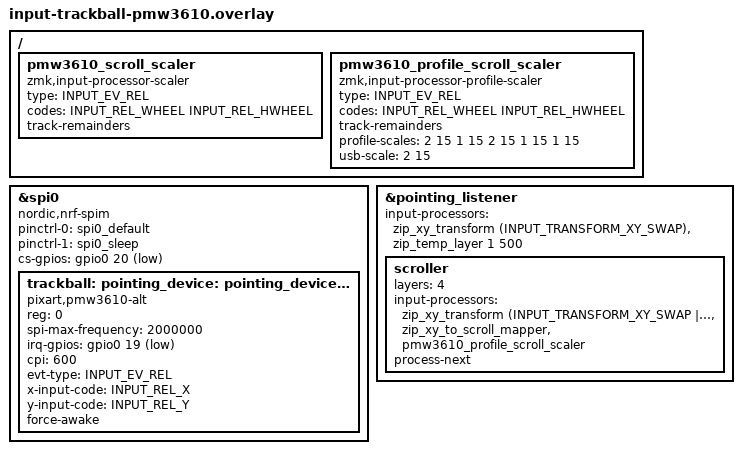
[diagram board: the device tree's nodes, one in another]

#include <dt-bindings/zmk/input_transform.h>

/ {
    pmw3610_scroll_scaler: pmw3610_scroll_scaler {
        compatible = "zmk,input-processor-scaler";
        #input-processor-cells = <2>;
        type = <INPUT_EV_REL>;
        codes = <INPUT_REL_WHEEL INPUT_REL_HWHEEL>;
        track-remainders;
    };

    /* BTプロファイルごとのスクロール速度 <倍率 除数>
     * 値 = 移動量 * 倍率 / 除数。除数を小さくするほど速い
     * CPI 600 用に補正済み（CPI 800 時の 1/20 = 600 時の 1/15）
     */
    pmw3610_profile_scroll_scaler: pmw3610_profile_scroll_scaler {
        compatible = "zmk,input-processor-profile-scaler";
        #input-processor-cells = <0>;
        type = <INPUT_EV_REL>;
        codes = <INPUT_REL_WHEEL INPUT_REL_HWHEEL>;
        track-remainders;
        profile-scales = <
            2 15   /* BT_SEL 0 : 2倍速 */
            1 15   /* BT_SEL 1 : 従来どおり */
            2 15   /* BT_SEL 2 : 2倍速 */
            1 15   /* BT_SEL 3 */
            1 15   /* BT_SEL 4 */
        >;
        usb-scale = <2 15>;  /* USB接続時 */
    };
};

&spi0 {
    status = "okay";
    compatible = "nordic,nrf-spim";
    pinctrl-0 = <&spi0_default>;
    pinctrl-1 = <&spi0_sleep>;
    pinctrl-names = "default", "sleep";
    cs-gpios = <&gpio0 20 GPIO_ACTIVE_LOW>;

    trackball: pointing_device: pointing_device@0 {
        status = "okay";
        compatible = "pixart,pmw3610-alt";
        reg = <0>;
        spi-max-frequency = <2000000>;
        irq-gpios = <&gpio0 19 (GPIO_ACTIVE_LOW | GPIO_PULL_UP)>;
        cpi = <600>;
        evt-type = <INPUT_EV_REL>;
        x-input-code = <INPUT_REL_X>;
        y-input-code = <INPUT_REL_Y>;
        force-awake;
    };
};

&pointing_listener {
    input-processors =
        <&zip_xy_transform (INPUT_TRANSFORM_XY_SWAP)>,
        <&zip_temp_layer 1 500>;

    scroller {
        layers = <4>;
        input-processors =
            <&zip_xy_transform (INPUT_TRANSFORM_XY_SWAP | INPUT_TRANSFORM_Y_INVERT)>,
            <&zip_xy_to_scroll_mapper>,
            <&pmw3610_profile_scroll_scaler>;
        process-next;
    };
};
